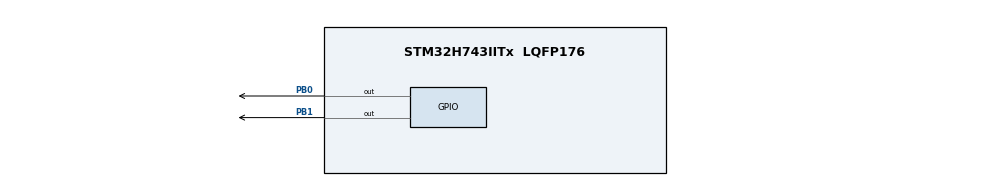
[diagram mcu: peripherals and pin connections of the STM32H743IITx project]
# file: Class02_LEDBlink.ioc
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Mcu.Family=STM32H7
Mcu.Name=STM32H743IITx
Mcu.Package=LQFP176
NVIC.PriorityGroup=NVIC_PRIORITYGROUP_4
PB0.Signal=GPIO_Output
PB1.Signal=GPIO_Output
PH0-OSC_IN.Mode=HSE-External-Oscillator
PH0-OSC_IN.Signal=RCC_OSC_IN
PH1-OSC_OUT.Mode=HSE-External-Oscillator
PH1-OSC_OUT.Signal=RCC_OSC_OUT
ProjectManager.HeapSize=0x200
ProjectManager.StackSize=0x400
ProjectManager.TargetToolchain=MDK-ARM V5
RCC.ADCFreq_Value=50390625
RCC.APB1Freq_Value=250000
RCC.APB2Freq_Value=250000
RCC.APB3Freq_Value=250000
RCC.APB4Freq_Value=250000
RCC.CortexFreq_Value=1000000
RCC.D1CPRE=RCC_SYSCLK_DIV4
RCC.D1PPRE=RCC_APB3_DIV2
RCC.D2PPRE1=RCC_APB1_DIV2
RCC.D2PPRE2=RCC_APB2_DIV2
RCC.D3PPRE=RCC_APB4_DIV2
RCC.DIVM1=1
RCC.DIVN1=38
RCC.DIVP1=38
RCC.HCLKFreq_Value=500000
RCC.HPRE=RCC_HCLK_DIV2
RCC.PLLSourceVirtual=RCC_PLLSOURCE_HSE
RCC.SYSCLKFreq_VALUE=4000000
RCC.SYSCLKSource=RCC_SYSCLKSOURCE_CSI
RCC.USBFreq_Value=475000000
board=custom

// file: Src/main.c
/**
  ******************************************************************************
  * @file           : main.c
  * @brief          : Main program body
  ******************************************************************************
  ** This notice applies to any and all portions of this file
  * that are not between comment pairs USER CODE BEGIN and
  * USER CODE END. Other portions of this file, whether
  * inserted by the user or by software development tools
  * are owned by their respective copyright owners.
  *
  * COPYRIGHT(c) 2018 STMicroelectronics
  *
  * Redistribution and use in source and binary forms, with or without modification,
  * are permitted provided that the following conditions are met:
  *   1. Redistributions of source code must retain the above copyright notice,
  *      this list of conditions and the following disclaimer.
  *   2. Redistributions in binary form must reproduce the above copyright notice,
  *      this list of conditions and the following disclaimer in the documentation
  *      and/or other materials provided with the distribution.
  *   3. Neither the name of STMicroelectronics nor the names of its contributors
  *      may be used to endorse or promote products derived from this software
  *      without specific prior written permission.
  *
  * THIS SOFTWARE IS PROVIDED BY THE COPYRIGHT HOLDERS AND CONTRIBUTORS "AS IS"
  * AND ANY EXPRESS OR IMPLIED WARRANTIES, INCLUDING, BUT NOT LIMITED TO, THE
  * IMPLIED WARRANTIES OF MERCHANTABILITY AND FITNESS FOR A PARTICULAR PURPOSE ARE
  * DISCLAIMED. IN NO EVENT SHALL THE COPYRIGHT HOLDER OR CONTRIBUTORS BE LIABLE
  * FOR ANY DIRECT, INDIRECT, INCIDENTAL, SPECIAL, EXEMPLARY, OR CONSEQUENTIAL
  * DAMAGES (INCLUDING, BUT NOT LIMITED TO, PROCUREMENT OF SUBSTITUTE GOODS OR
  * SERVICES; LOSS OF USE, DATA, OR PROFITS; OR BUSINESS INTERRUPTION) HOWEVER
  * CAUSED AND ON ANY THEORY OF LIABILITY, WHETHER IN CONTRACT, STRICT LIABILITY,
  * OR TORT (INCLUDING NEGLIGENCE OR OTHERWISE) ARISING IN ANY WAY OUT OF THE USE
  * OF THIS SOFTWARE, EVEN IF ADVISED OF THE POSSIBILITY OF SUCH DAMAGE.
  *
  ******************************************************************************
  */
#include "main.h"
#include "stm32h7xx_hal.h"

/* USER CODE BEGIN PV */
/* Private variables ---------------------------------------------------------*/

/* USER CODE END PV */

void SystemClock_Config(void);
void SystemClock_Config_400(void);
static void MX_GPIO_Init(void);

/* USER CODE BEGIN PFP */
/* Private function prototypes -----------------------------------------------*/

/* USER CODE END PFP */

/* USER CODE BEGIN 0 */
unsigned int cnt = 0;
unsigned long dcnt = 0xffff;
/* USER CODE END 0 */

int main(void)
{

  /* MCU Configuration----------------------------------------------------------*/

  /* Reset of all peripherals, Initializes the Flash interface and the Systick. */
  HAL_Init();

  /* Configure the system clock */
  SystemClock_Config();

  /* Initialize all configured peripherals */
  MX_GPIO_Init();

  /* Infinite loop */
  /* USER CODE BEGIN WHILE */
  while (1)
  {
		cnt++;
		if(cnt == 20)
			SystemClock_Config_400();
  /* USER CODE END WHILE */

  /* USER CODE BEGIN 3 */
		HAL_GPIO_TogglePin(GPIOB,GPIO_PIN_1);
		while(dcnt--);
		dcnt = 0x1fffff;
		//HAL_Delay(100);
		HAL_GPIO_TogglePin(GPIOB,GPIO_PIN_0);
  }
  /* USER CODE END 3 */

}

void SystemClock_Config(void)
{

  RCC_OscInitTypeDef RCC_OscInitStruct;
  RCC_ClkInitTypeDef RCC_ClkInitStruct;

    /**Supply configuration update enable
    */
  MODIFY_REG(PWR->CR3, PWR_CR3_SCUEN, 0);

    /**Configure the main internal regulator output voltage
    */
  __HAL_PWR_VOLTAGESCALING_CONFIG(PWR_REGULATOR_VOLTAGE_SCALE3);

  while ((PWR->D3CR & (PWR_D3CR_VOSRDY)) != PWR_D3CR_VOSRDY)
  {

  }
    /**Initializes the CPU, AHB and APB busses clocks
    */
  RCC_OscInitStruct.OscillatorType = RCC_OSCILLATORTYPE_CSI;
  RCC_OscInitStruct.CSIState = RCC_CSI_ON;
  RCC_OscInitStruct.CSICalibrationValue = 16;
  RCC_OscInitStruct.PLL.PLLState = RCC_PLL_NONE;
  if (HAL_RCC_OscConfig(&RCC_OscInitStruct) != HAL_OK)
  {
    _Error_Handler(__FILE__, __LINE__);
  }

    /**Initializes the CPU, AHB and APB busses clocks
    */
  RCC_ClkInitStruct.ClockType = RCC_CLOCKTYPE_HCLK|RCC_CLOCKTYPE_SYSCLK
                              |RCC_CLOCKTYPE_PCLK1|RCC_CLOCKTYPE_PCLK2
                              |RCC_CLOCKTYPE_D3PCLK1|RCC_CLOCKTYPE_D1PCLK1;
  RCC_ClkInitStruct.SYSCLKSource = RCC_SYSCLKSOURCE_CSI;
  RCC_ClkInitStruct.SYSCLKDivider = RCC_SYSCLK_DIV4;
  RCC_ClkInitStruct.AHBCLKDivider = RCC_HCLK_DIV2;
  RCC_ClkInitStruct.APB3CLKDivider = RCC_APB3_DIV2;
  RCC_ClkInitStruct.APB1CLKDivider = RCC_APB1_DIV2;
  RCC_ClkInitStruct.APB2CLKDivider = RCC_APB2_DIV2;
  RCC_ClkInitStruct.APB4CLKDivider = RCC_APB4_DIV2;

  if (HAL_RCC_ClockConfig(&RCC_ClkInitStruct, FLASH_LATENCY_0) != HAL_OK)
  {
    _Error_Handler(__FILE__, __LINE__);
  }

    /**Configure the Systick interrupt time
    */
  HAL_SYSTICK_Config(SystemCoreClock/1000);

    /**Configure the Systick
    */
  HAL_SYSTICK_CLKSourceConfig(SYSTICK_CLKSOURCE_HCLK);

  /* SysTick_IRQn interrupt configuration */
  HAL_NVIC_SetPriority(SysTick_IRQn, 0, 0);
}

/** Configure pins as
        * Analog
        * Input
        * Output
        * EVENT_OUT
        * EXTI
*/
static void MX_GPIO_Init(void)
{

  GPIO_InitTypeDef GPIO_InitStruct;

  /* GPIO Ports Clock Enable */
  __HAL_RCC_GPIOH_CLK_ENABLE();
  __HAL_RCC_GPIOB_CLK_ENABLE();

  /*Configure GPIO pin Output Level */
  HAL_GPIO_WritePin(GPIOB, GPIO_PIN_0|GPIO_PIN_1, GPIO_PIN_RESET);

  /*Configure GPIO pins : PB0 PB1 */
  GPIO_InitStruct.Pin = GPIO_PIN_0|GPIO_PIN_1;
  GPIO_InitStruct.Mode = GPIO_MODE_OUTPUT_PP;
  GPIO_InitStruct.Pull = GPIO_NOPULL;
  GPIO_InitStruct.Speed = GPIO_SPEED_FREQ_LOW;
  HAL_GPIO_Init(GPIOB, &GPIO_InitStruct);

}

/* USER CODE BEGIN 4 */
/**
  * @brief System Clock Configuration
  * @retval None
  */
void SystemClock_Config_400(void)
{

  RCC_OscInitTypeDef RCC_OscInitStruct;
  RCC_ClkInitTypeDef RCC_ClkInitStruct;

    /**Supply configuration update enable
    */
  MODIFY_REG(PWR->CR3, PWR_CR3_SCUEN, 0);

    /**Configure the main internal regulator output voltage
    */
  __HAL_PWR_VOLTAGESCALING_CONFIG(PWR_REGULATOR_VOLTAGE_SCALE1);

  while ((PWR->D3CR & (PWR_D3CR_VOSRDY)) != PWR_D3CR_VOSRDY)
  {

  }
    /**Initializes the CPU, AHB and APB busses clocks
    */
  RCC_OscInitStruct.OscillatorType = RCC_OSCILLATORTYPE_HSE;
  RCC_OscInitStruct.HSEState = RCC_HSE_ON;
  RCC_OscInitStruct.PLL.PLLState = RCC_PLL_ON;
  RCC_OscInitStruct.PLL.PLLSource = RCC_PLLSOURCE_HSE;
  RCC_OscInitStruct.PLL.PLLM = 2;
  RCC_OscInitStruct.PLL.PLLN = 64;
  RCC_OscInitStruct.PLL.PLLP = 2;
  RCC_OscInitStruct.PLL.PLLQ = 2;
  RCC_OscInitStruct.PLL.PLLR = 2;
  RCC_OscInitStruct.PLL.PLLRGE = RCC_PLL1VCIRANGE_3;
  RCC_OscInitStruct.PLL.PLLVCOSEL = RCC_PLL1VCOWIDE;
  RCC_OscInitStruct.PLL.PLLFRACN = 0;
  if (HAL_RCC_OscConfig(&RCC_OscInitStruct) != HAL_OK)
  {
    _Error_Handler(__FILE__, __LINE__);
  }

    /**Initializes the CPU, AHB and APB busses clocks
    */
  RCC_ClkInitStruct.ClockType = RCC_CLOCKTYPE_HCLK|RCC_CLOCKTYPE_SYSCLK
                              |RCC_CLOCKTYPE_PCLK1|RCC_CLOCKTYPE_PCLK2
                              |RCC_CLOCKTYPE_D3PCLK1|RCC_CLOCKTYPE_D1PCLK1;
  RCC_ClkInitStruct.SYSCLKSource = RCC_SYSCLKSOURCE_PLLCLK;
  RCC_ClkInitStruct.SYSCLKDivider = RCC_SYSCLK_DIV1;
  RCC_ClkInitStruct.AHBCLKDivider = RCC_HCLK_DIV2;
  RCC_ClkInitStruct.APB3CLKDivider = RCC_APB3_DIV2;
  RCC_ClkInitStruct.APB1CLKDivider = RCC_APB1_DIV2;
  RCC_ClkInitStruct.APB2CLKDivider = RCC_APB2_DIV2;
  RCC_ClkInitStruct.APB4CLKDivider = RCC_APB4_DIV2;

  if (HAL_RCC_ClockConfig(&RCC_ClkInitStruct, FLASH_LATENCY_2) != HAL_OK)
  {
    _Error_Handler(__FILE__, __LINE__);
  }

    /**Configure the Systick interrupt time
    */
  HAL_SYSTICK_Config(SystemCoreClock/1000);

    /**Configure the Systick
    */
  HAL_SYSTICK_CLKSourceConfig(SYSTICK_CLKSOURCE_HCLK);

  /* SysTick_IRQn interrupt configuration */
  HAL_NVIC_SetPriority(SysTick_IRQn, 0, 0);
}
/* USER CODE END 4 */

void _Error_Handler(char *file, int line)
{
  while(1)
  {
  }
}

/************************ (C) COPYRIGHT STMicroelectronics *****END OF FILE****/
